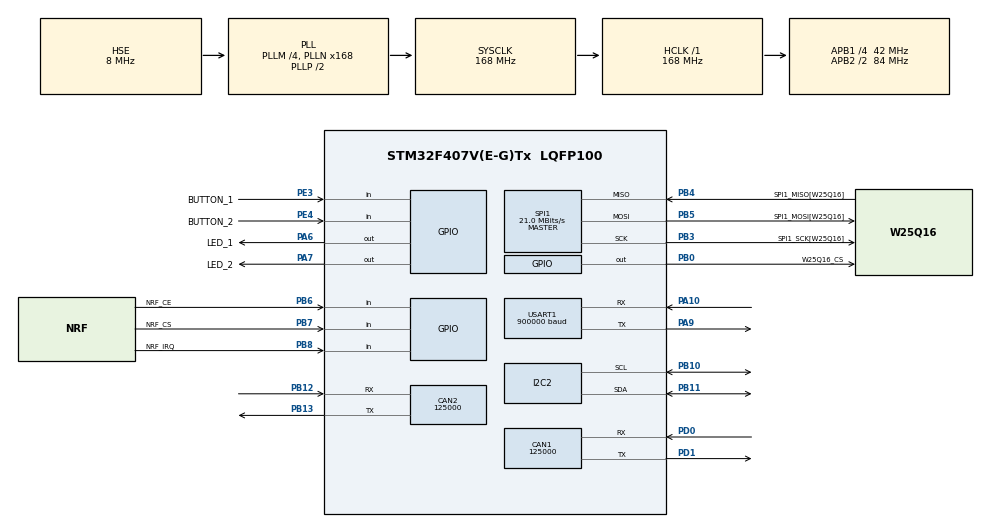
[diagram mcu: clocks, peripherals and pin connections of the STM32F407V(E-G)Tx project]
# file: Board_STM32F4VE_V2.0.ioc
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CAN1.ABOM=ENABLE
CAN1.AWUM=ENABLE
CAN1.BS1=CAN_BS1_12TQ
CAN1.BS2=CAN_BS2_8TQ
CAN1.CalculateBaudRate=125000
CAN1.CalculateTimeBit=8000
CAN1.CalculateTimeQuantum=380.95238095238096
CAN1.NART=ENABLE
CAN2.ABOM=ENABLE
CAN2.AWUM=ENABLE
CAN2.BS1=CAN_BS1_12TQ
CAN2.BS2=CAN_BS2_8TQ
CAN2.CalculateBaudRate=125000
CAN2.CalculateTimeBit=8000
CAN2.CalculateTimeQuantum=380.95238095238096
CAN2.NART=ENABLE
Dma.Request0=USART1_RX
Dma.USART1_RX.0.Direction=DMA_PERIPH_TO_MEMORY
Dma.USART1_RX.0.FIFOMode=DMA_FIFOMODE_DISABLE
Dma.USART1_RX.0.Instance=DMA2_Stream2
Dma.USART1_RX.0.MemDataAlignment=DMA_MDATAALIGN_BYTE
Dma.USART1_RX.0.MemInc=DMA_MINC_ENABLE
Dma.USART1_RX.0.Mode=DMA_CIRCULAR
Dma.USART1_RX.0.PeriphDataAlignment=DMA_PDATAALIGN_BYTE
Dma.USART1_RX.0.PeriphInc=DMA_PINC_DISABLE
Dma.USART1_RX.0.Priority=DMA_PRIORITY_MEDIUM
FREERTOS.Tasks01=defaultTask,24,512,StartDefaultTask,Default,NULL,Dynamic,NULL,NULL
FREERTOS.configTOTAL_HEAP_SIZE=40000
FREERTOS.configUSE_NEWLIB_REENTRANT=1
Mcu.Family=STM32F4
Mcu.Name=STM32F407V(E-G)Tx
Mcu.Package=LQFP100
NVIC.CAN1_RX0_IRQn=true\:5\:0\:true\:false\:true\:true\:true\:false\:true
NVIC.CAN1_TX_IRQn=true\:5\:0\:true\:false\:true\:true\:true\:false\:true
NVIC.CAN2_RX0_IRQn=true\:5\:0\:true\:false\:true\:true\:true\:false\:true
NVIC.CAN2_TX_IRQn=true\:5\:0\:true\:false\:true\:true\:true\:false\:true
NVIC.DMA2_Stream2_IRQn=true\:3\:0\:true\:false\:true\:false\:false\:true\:true
NVIC.I2C2_ER_IRQn=true\:4\:0\:true\:false\:true\:false\:true\:true\:true
NVIC.I2C2_EV_IRQn=true\:4\:0\:true\:false\:true\:false\:true\:true\:true
NVIC.PriorityGroup=NVIC_PRIORITYGROUP_4
NVIC.TIM4_IRQn=true\:1\:0\:true\:false\:true\:false\:true\:false\:true
NVIC.TIM8_UP_TIM13_IRQn=true\:15\:0\:false\:false\:true\:false\:false\:true\:true
NVIC.TimeBase=TIM8_UP_TIM13_IRQn
NVIC.TimeBaseIP=TIM13
NVIC.USART1_IRQn=true\:2\:0\:true\:false\:true\:false\:true\:false\:true
PA10.GPIO_PuPd=GPIO_PULLUP
PA10.Mode=Asynchronous
PA10.Signal=USART1_RX
PA11.Signal=USB_OTG_FS_DM
PA12.Signal=USB_OTG_FS_DP
PA13.Mode=Serial_Wire
PA13.Signal=SYS_JTMS-SWDIO
PA14.Mode=Serial_Wire
PA14.Signal=SYS_JTCK-SWCLK
PA6.GPIO_Label=LED_1
PA6.Signal=GPIO_Output
PA7.GPIO_Label=LED_2
PA7.Signal=GPIO_Output
PA9.Mode=Asynchronous
PA9.Signal=USART1_TX
PB0.GPIO_Label=W25Q16_CS
PB0.Signal=GPIO_Output
PB10.GPIO_Pu=GPIO_PULLUP
PB10.Mode=I2C
PB10.Signal=I2C2_SCL
PB11.GPIO_Pu=GPIO_PULLUP
PB11.Mode=I2C
PB11.Signal=I2C2_SDA
PB12.Mode=CAN_Activate
PB12.Signal=CAN2_RX
PB13.Mode=CAN_Activate
PB13.Signal=CAN2_TX
PB3.GPIO_Label=SPI1_SCK[W25Q16]
PB3.Mode=Full_Duplex_Master
PB3.Signal=SPI1_SCK
PB4.GPIO_Label=SPI1_MISO[W25Q16]
PB4.Mode=Full_Duplex_Master
PB4.Signal=SPI1_MISO
PB5.GPIO_Label=SPI1_MOSI[W25Q16]
PB5.Mode=Full_Duplex_Master
PB5.Signal=SPI1_MOSI
PB6.GPIO_Label=NRF_CE
PB6.Signal=GPIO_Input
PB7.GPIO_Label=NRF_CS
PB7.Signal=GPIO_Input
PB8.GPIO_Label=NRF_IRQ
PB8.Signal=GPIO_Input
PC10.Signal=SDIO_D2
PC11.Signal=SDIO_D3
PC12.Signal=SDIO_CK
PC14-OSC32_IN.Mode=LSE-External-Oscillator
PC14-OSC32_IN.Signal=RCC_OSC32_IN
PC15-OSC32_OUT.Mode=LSE-External-Oscillator
PC15-OSC32_OUT.Signal=RCC_OSC32_OUT
PC8.Signal=SDIO_D0
PC9.Signal=SDIO_D1
PD0.Mode=CAN_Activate
PD0.Signal=CAN1_RX
PD1.Mode=CAN_Activate
PD1.Signal=CAN1_TX
PD2.Signal=SDIO_CMD
PE3.GPIO_Label=BUTTON_1
PE3.GPIO_PuPd=GPIO_PULLUP
PE3.Signal=GPIO_Input
PE4.GPIO_Label=BUTTON_2
PE4.GPIO_PuPd=GPIO_PULLUP
PE4.Signal=GPIO_Input
PH0-OSC_IN.Mode=HSE-External-Oscillator
PH0-OSC_IN.Signal=RCC_OSC_IN
PH1-OSC_OUT.Mode=HSE-External-Oscillator
PH1-OSC_OUT.Signal=RCC_OSC_OUT
ProjectManager.HeapSize=0x000
ProjectManager.StackSize=0x300
ProjectManager.TargetToolchain=STM32CubeIDE
RCC.48MHZClocksFreq_Value=48000000
RCC.AHBFreq_Value=168000000
RCC.APB1CLKDivider=RCC_HCLK_DIV4
RCC.APB1Freq_Value=42000000
RCC.APB1TimFreq_Value=84000000
RCC.APB2CLKDivider=RCC_HCLK_DIV2
RCC.APB2Freq_Value=84000000
RCC.APB2TimFreq_Value=168000000
RCC.CortexFreq_Value=168000000
RCC.HCLKFreq_Value=168000000
RCC.HSE_VALUE=8000000
RCC.HSI_VALUE=16000000
RCC.PLLM=4
RCC.PLLN=168
RCC.PLLQ=7
RCC.PLLSourceVirtual=RCC_PLLSOURCE_HSE
RCC.SYSCLKFreq_VALUE=168000000
RCC.SYSCLKSource=RCC_SYSCLKSOURCE_PLLCLK
RCC.VCOOutputFreq_Value=336000000
SPI1.BaudRatePrescaler=SPI_BAUDRATEPRESCALER_4
SPI1.CalculateBaudRate=21.0 MBits/s
SPI1.Direction=SPI_DIRECTION_2LINES
SPI1.Mode=SPI_MODE_MASTER
SPI1.VirtualType=VM_MASTER
TIM4.Period=999
TIM4.Prescaler=83
TIM4.TIM_MasterOutputTrigger=TIM_TRGO_UPDATE
USART1.BaudRate=900000
USART1.VirtualMode=VM_ASYNC
VP_CRC_VS_CRC.Mode=CRC_Activate
VP_FREERTOS_VS_CMSIS_V2.Mode=CMSIS_V2
VP_RNG_VS_RNG.Mode=RNG_Activate
VP_SYS_VS_tim13.Mode=TIM13
VP_TIM4_VS_ClockSourceINT.Mode=Internal
board=custom

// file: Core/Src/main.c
/* USER CODE BEGIN Header */
/**
  ******************************************************************************
  * @file           : main.c
  * @brief          : Main program body
  ******************************************************************************
  * @attention
  *
  * Copyright (c) 2022 STMicroelectronics.
  * All rights reserved.
  *
  * This software is licensed under terms that can be found in the LICENSE file
  * in the root directory of this software component.
  * If no LICENSE file comes with this software, it is provided AS-IS.
  *
  ******************************************************************************
  */
/* USER CODE END Header */
#include "main.h"
#include "cmsis_os.h"
#include "can.h"
#include "crc.h"
#include "dma.h"
#include "i2c.h"
#include "rng.h"
#include "spi.h"
#include "tim.h"
#include "usart.h"
#include "gpio.h"

/* USER CODE BEGIN Includes */
#include "Components.h"
/* USER CODE END Includes */

/* USER CODE BEGIN PD */
#define CCMRAM_SECTION_START_ADDRESS 0x10000000
#define CCMRAM_SECTION_SIZE 0x10000
/* USER CODE END PD */

/* USER CODE BEGIN PV */
//==============================================================================

//==============================================================================
/* USER CODE END PV */

void SystemClock_Config(void);
void MX_FREERTOS_Init(void);

int main(void)
{
  /* USER CODE BEGIN 1 */
	memset((void*)CCMRAM_SECTION_START_ADDRESS, 0, CCMRAM_SECTION_SIZE);
  /* USER CODE END 1 */

  /* MCU Configuration--------------------------------------------------------*/

  /* Reset of all peripherals, Initializes the Flash interface and the Systick. */
  HAL_Init();

  /* Configure the system clock */
  SystemClock_Config();

  /* Initialize all configured peripherals */
  MX_GPIO_Init();
  MX_DMA_Init();
  MX_RNG_Init();
  MX_CRC_Init();
  MX_TIM4_Init();
  MX_SPI1_Init();
  MX_I2C2_Init();
  MX_USART1_UART_Init();
  MX_CAN1_Init();
  MX_CAN2_Init();
  /* USER CODE BEGIN 2 */
#if FREERTOS_USED == 0
	ComponentsInit(main);
#endif
  /* USER CODE END 2 */

  /* Init scheduler */
  osKernelInitialize();  /* Call init function for freertos objects (in freertos.c) */
  MX_FREERTOS_Init();

  /* Start scheduler */
  osKernelStart();
  /* We should never get here as control is now taken by the scheduler */
  /* Infinite loop */
  while (1)
  {

    /* USER CODE BEGIN 3 */
#if FREERTOS_USED == 0
		ComponentsHandler();
#endif
  }
  /* USER CODE END 3 */
}

void SystemClock_Config(void)
{
  RCC_OscInitTypeDef RCC_OscInitStruct = {0};
  RCC_ClkInitTypeDef RCC_ClkInitStruct = {0};

  /** Configure the main internal regulator output voltage
  */
  __HAL_RCC_PWR_CLK_ENABLE();
  __HAL_PWR_VOLTAGESCALING_CONFIG(PWR_REGULATOR_VOLTAGE_SCALE1);

  /** Initializes the RCC Oscillators according to the specified parameters
  * in the RCC_OscInitTypeDef structure.
  */
  RCC_OscInitStruct.OscillatorType = RCC_OSCILLATORTYPE_HSE;
  RCC_OscInitStruct.HSEState = RCC_HSE_ON;
  RCC_OscInitStruct.PLL.PLLState = RCC_PLL_ON;
  RCC_OscInitStruct.PLL.PLLSource = RCC_PLLSOURCE_HSE;
  RCC_OscInitStruct.PLL.PLLM = 4;
  RCC_OscInitStruct.PLL.PLLN = 168;
  RCC_OscInitStruct.PLL.PLLP = RCC_PLLP_DIV2;
  RCC_OscInitStruct.PLL.PLLQ = 7;
  if (HAL_RCC_OscConfig(&RCC_OscInitStruct) != HAL_OK)
  {
    Error_Handler();
  }

  /** Initializes the CPU, AHB and APB buses clocks
  */
  RCC_ClkInitStruct.ClockType = RCC_CLOCKTYPE_HCLK|RCC_CLOCKTYPE_SYSCLK
                              |RCC_CLOCKTYPE_PCLK1|RCC_CLOCKTYPE_PCLK2;
  RCC_ClkInitStruct.SYSCLKSource = RCC_SYSCLKSOURCE_PLLCLK;
  RCC_ClkInitStruct.AHBCLKDivider = RCC_SYSCLK_DIV1;
  RCC_ClkInitStruct.APB1CLKDivider = RCC_HCLK_DIV4;
  RCC_ClkInitStruct.APB2CLKDivider = RCC_HCLK_DIV2;

  if (HAL_RCC_ClockConfig(&RCC_ClkInitStruct, FLASH_LATENCY_5) != HAL_OK)
  {
    Error_Handler();
  }
}

void HAL_TIM_PeriodElapsedCallback(TIM_HandleTypeDef *htim)
{
  if (htim->Instance == TIM13) {
    HAL_IncTick();
  }
}

void Error_Handler(void)
{
  __disable_irq();
  while (1)
  {
  }
}

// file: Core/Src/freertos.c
/* USER CODE BEGIN Header */
/**
  ******************************************************************************
  * File Name          : freertos.c
  * Description        : Code for freertos applications
  ******************************************************************************
  * @attention
  *
  * Copyright (c) 2024 STMicroelectronics.
  * All rights reserved.
  *
  * This software is licensed under terms that can be found in the LICENSE file
  * in the root directory of this software component.
  * If no LICENSE file comes with this software, it is provided AS-IS.
  *
  ******************************************************************************
  */
/* USER CODE END Header */

#include "FreeRTOS.h"
#include "task.h"
#include "main.h"
#include "cmsis_os.h"

/* USER CODE BEGIN Includes */
#include "Components.h"
/* USER CODE END Includes */

/* USER CODE BEGIN Variables */
uint8_t ucHeap[configTOTAL_HEAP_SIZE] FREERTOS_HEAP_SECTION;
/* USER CODE END Variables */
/* Definitions for defaultTask */
osThreadId_t defaultTaskHandle;
const osThreadAttr_t defaultTask_attributes = {
  .name = "defaultTask",
  .stack_size = 128 * 4,
  .priority = (osPriority_t) osPriorityNormal,
};

void StartDefaultTask(void *argument);

void MX_FREERTOS_Init(void); /* (MISRA C 2004 rule 8.1) */

void MX_FREERTOS_Init(void) {

  /* Create the thread(s) */
  /* creation of defaultTask */
  defaultTaskHandle = osThreadNew(StartDefaultTask, NULL, &defaultTask_attributes);

}

void StartDefaultTask(void *argument)
{
  /* USER CODE BEGIN StartDefaultTask */
	ComponentsInit(argument);
	/* Infinite loop */
  for(;;)
  {
	  ComponentsHandler();
  }
  /* USER CODE END StartDefaultTask */
}
